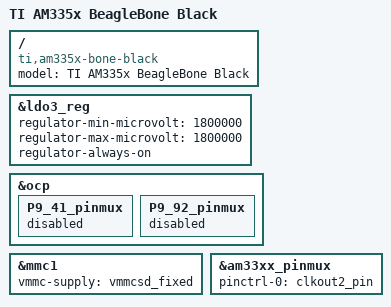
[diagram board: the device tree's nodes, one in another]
/*
 * Copyright (C) 2012 Texas Instruments Incorporated - http://www.ti.com/
 *
 * This program is free software; you can redistribute it and/or modify
 * it under the terms of the GNU General Public License version 2 as
 * published by the Free Software Foundation.
 */
/dts-v1/;

#include "am33xx.dtsi"
#include "am335x-bone-common.dtsi"
#include "am335x-bone-common-pinmux.dtsi"

/ {
	model = "TI AM335x BeagleBone Black";
	compatible = "ti,am335x-bone-black", "ti,am335x-bone", "ti,am33xx";
};

&ldo3_reg {
	regulator-min-microvolt = <1800000>;
	regulator-max-microvolt = <1800000>;
	regulator-always-on;
};

&ocp {
	/* clkout2 */
	P9_41_pinmux {
		status = "disabled";
	};
	/* mmc1 */
	P9_92_pinmux {
		status = "disabled";
	};
};

&mmc1 {
	vmmc-supply = <&vmmcsd_fixed>;
};

&am33xx_pinmux {
	pinctrl-names = "default";
	pinctrl-0 = <&clkout2_pin>;
};


#include "am335x-bone-bb-view-43.dtsi"

#include "am335x-boneblack-emmc.dtsi"
/* HDMI: with audio */
/* #include "am335x-boneblack-nxp-hdmi-audio.dtsi" */
/* HDMI: without audio */
/* #include "am335x-boneblack-nxp-hdmi-no-audio.dtsi" */

/* can0: P9.19, P9.20: disable: i2c2: cape eeprom */
/* can0: peripheral */
/* #include "am335x-can0.dtsi" */
/* can0: pinmux */
/* #include "am335x-bone-can0.dtsi" */

/* can1: P9_24, P9_26 */
/* #include "am335x-can1.dtsi" */
/* #include "am335x-bone-can1.dtsi" */

/* i2c2: cape eeprom */
/* P9.19 P9.20 */
/* #include "am335x-bone-i2c2-cape-eeprom.dtsi" */

/* spi0: */
/* P9.17 spi0_cs0 */
/* P9.18 spi0_d1 */
/* P9.21 spi0_d0 */
/* P9.22 spi0_sclk */
#include "am335x-bone-spi0-spidev.dtsi"

/* spi1: */
/* P9.31 spi1_sclk */
/* P9.29 spi1_d0 */
/* P9.30 spi1_d1 */
/* P9.28 spi1_cs0 */
#include "am335x-bone-spi1-spidev.dtsi"

/* spi1a: */
/* P9.42 spi1_sclk */
/* P9.29 spi1_d0 */
/* P9.30 spi1_d1 */
/* P9.20 spi1_cs0 */
/* #include "am335x-bone-spi1a-spidev.dtsi" */


/* eQEP0 */
/* P9.41 eqep0_index */
/* P9.25 eqep0_strobe */
/* P9.42 eqep0A_in */
/* P9.27 eqep0B_in */
#include "am335x-bone-eqep0.dts"

/* eQEP2b */
/* P8.14 eqep2b_index */
/* P8.15 eqep2b_strobe */
/* P8.12 eqep2bA_in */
/* P8.13 eqep2bB_in */
#include "am335x-bone-eqep2b.dts"

/* uart1: P9.24, P9.26 */
#include "am335x-ttyO1.dtsi"
/* #include "am335x-bone-ttyO1.dtsi" */

/* uart2: P9.21, P9.22 */
#include "am335x-ttyO2.dtsi"
/* #include "am335x-bone-ttyO2.dtsi" */

/* uart4: P9.11, P9.13 */
#include "am335x-ttyO4.dtsi"
/* #include "am335x-bone-ttyO4.dtsi" */

/* uart5: P8.37, P8.38 boneblack: hdmi has to be disabled for ttyO5 */
#include "am335x-ttyO5.dtsi"
/* #include "am335x-bone-ttyO5.dtsi" */

#include "am335x-bone-jmc8-addons.dts"

